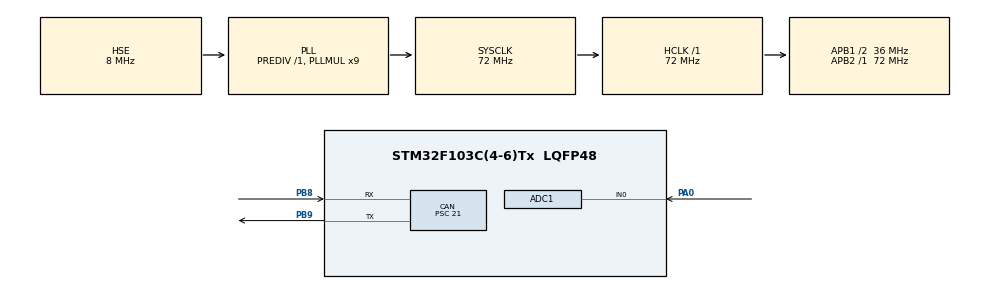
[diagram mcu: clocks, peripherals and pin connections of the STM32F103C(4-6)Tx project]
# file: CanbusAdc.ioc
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ADC1.Channel-0\#ChannelRegularConversion=ADC_CHANNEL_0
ADC1.ContinuousConvMode=ENABLE
ADC1.NbrOfConversion=1
ADC1.NbrOfConversionFlag=1
ADC1.Rank-0\#ChannelRegularConversion=1
ADC1.SamplingTime-0\#ChannelRegularConversion=ADC_SAMPLETIME_55CYCLES_5
ADC1.master=1
CAN.BS1=CAN_BS1_12TQ
CAN.BS2=CAN_BS2_4TQ
CAN.CalculateBaudRate=100840
CAN.CalculateTimeBit=9916
CAN.CalculateTimeQuantum=583.3333333333334
CAN.Prescaler=21
Mcu.Family=STM32F1
Mcu.Name=STM32F103C(4-6)Tx
Mcu.Package=LQFP48
NVIC.PriorityGroup=NVIC_PRIORITYGROUP_4
NVIC.USB_LP_CAN1_RX0_IRQn=true\:0\:0\:false\:false\:true\:true\:true\:true
PA0-WKUP.Signal=ADCx_IN0
PA13.Mode=Serial_Wire
PA13.Signal=SYS_JTMS-SWDIO
PA14.Mode=Serial_Wire
PA14.Signal=SYS_JTCK-SWCLK
PB8.Mode=CAN_Activate
PB8.Signal=CAN_RX
PB9.Mode=CAN_Activate
PB9.Signal=CAN_TX
PD0-OSC_IN.Mode=HSE-External-Oscillator
PD0-OSC_IN.Signal=RCC_OSC_IN
PD1-OSC_OUT.Mode=HSE-External-Oscillator
PD1-OSC_OUT.Signal=RCC_OSC_OUT
ProjectManager.HeapSize=0x200
ProjectManager.StackSize=0x400
ProjectManager.TargetToolchain=STM32CubeIDE
RCC.ADCPresc=RCC_ADCPCLK2_DIV6
RCC.AHBFreq_Value=72000000
RCC.APB1CLKDivider=RCC_HCLK_DIV2
RCC.APB1Freq_Value=36000000
RCC.APB1TimFreq_Value=72000000
RCC.APB2Freq_Value=72000000
RCC.APB2TimFreq_Value=72000000
RCC.HCLKFreq_Value=72000000
RCC.PLLMUL=RCC_PLL_MUL9
RCC.PLLSourceVirtual=RCC_PLLSOURCE_HSE
RCC.SYSCLKFreq_VALUE=72000000
RCC.SYSCLKSource=RCC_SYSCLKSOURCE_PLLCLK
RCC.USBFreq_Value=72000000
SH.ADCx_IN0.0=ADC1_IN0,IN0
board=custom

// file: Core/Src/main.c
/* USER CODE BEGIN Header */
/**
  ******************************************************************************
  * @file           : main.c
  * @brief          : Main program body
  ******************************************************************************
  * @attention
  *
  * Copyright (c) 2024 STMicroelectronics.
  * All rights reserved.
  *
  * This software is licensed under terms that can be found in the LICENSE file
  * in the root directory of this software component.
  * If no LICENSE file comes with this software, it is provided AS-IS.
  *
  ******************************************************************************
  */
/* USER CODE END Header */
#include "main.h"

ADC_HandleTypeDef hadc1;

CAN_HandleTypeDef hcan;

/* USER CODE BEGIN PV */

uint8_t adcData;
uint32_t pTxMailbox;

CAN_TxHeaderTypeDef pHeader;
CAN_FilterTypeDef sFilterConfig;

/* USER CODE END PV */

void SystemClock_Config(void);
static void MX_GPIO_Init(void);
static void MX_CAN_Init(void);
static void MX_ADC1_Init(void);

int main(void)
{

  /* MCU Configuration--------------------------------------------------------*/

  /* Reset of all peripherals, Initializes the Flash interface and the Systick. */
  HAL_Init();

  /* Configure the system clock */
  SystemClock_Config();

  /* Initialize all configured peripherals */
  MX_GPIO_Init();
  MX_CAN_Init();
  MX_ADC1_Init();
  /* USER CODE BEGIN 2 */
  	  //Set transmit parameters
  	  	  pHeader.DLC = 1; // length of message (1 == 8bit message)
  	  	  pHeader.IDE = CAN_ID_STD; // Standard or extended
  	  	  pHeader.RTR = CAN_RTR_DATA; // if you write data it means the card send data
  	  	  pHeader.StdId = 0x0112;

  	  // Set filter parameter
  	  	  sFilterConfig.FilterActivation = ENABLE;
  	  	  sFilterConfig.FilterBank = 0;
  	  	  sFilterConfig.FilterFIFOAssignment = CAN_FILTER_FIFO0;
  	  	  sFilterConfig.FilterIdHigh = 0x0000;
  	  	  sFilterConfig.FilterIdLow = 0x0000;
  	  	  sFilterConfig.FilterMaskIdHigh = 0x0000;
  	  	  sFilterConfig.FilterMaskIdLow = 0x0000;
  	  	  sFilterConfig.FilterMode = CAN_FILTERMODE_IDMASK; // if you want to communicate with actual id number you can choose list
  	  	  sFilterConfig.FilterScale = CAN_FILTERSCALE_16BIT; // 16 bit because i use std id

  	  	  HAL_CAN_ConfigFilter(&hcan, &sFilterConfig);
  	  //Start Can communication
  	  	  HAL_CAN_Start(&hcan);
  	  //Start Adc with DMA
  	  	  HAL_ADC_Start_DMA(&hadc1, &adcData, 1);

  /* USER CODE END 2 */

  /* Infinite loop */
  while (1)
  {

    /* USER CODE BEGIN 3 */
	  HAL_CAN_AddTxMessage(&hcan, &pHeader, &adcData, &pTxMailbox);
  }
  /* USER CODE END 3 */
}

void SystemClock_Config(void)
{
  RCC_OscInitTypeDef RCC_OscInitStruct = {0};
  RCC_ClkInitTypeDef RCC_ClkInitStruct = {0};
  RCC_PeriphCLKInitTypeDef PeriphClkInit = {0};

  /** Initializes the RCC Oscillators according to the specified parameters
  * in the RCC_OscInitTypeDef structure.
  */
  RCC_OscInitStruct.OscillatorType = RCC_OSCILLATORTYPE_HSE;
  RCC_OscInitStruct.HSEState = RCC_HSE_ON;
  RCC_OscInitStruct.HSEPredivValue = RCC_HSE_PREDIV_DIV1;
  RCC_OscInitStruct.HSIState = RCC_HSI_ON;
  RCC_OscInitStruct.PLL.PLLState = RCC_PLL_ON;
  RCC_OscInitStruct.PLL.PLLSource = RCC_PLLSOURCE_HSE;
  RCC_OscInitStruct.PLL.PLLMUL = RCC_PLL_MUL9;
  if (HAL_RCC_OscConfig(&RCC_OscInitStruct) != HAL_OK)
  {
    Error_Handler();
  }

  /** Initializes the CPU, AHB and APB buses clocks
  */
  RCC_ClkInitStruct.ClockType = RCC_CLOCKTYPE_HCLK|RCC_CLOCKTYPE_SYSCLK
                              |RCC_CLOCKTYPE_PCLK1|RCC_CLOCKTYPE_PCLK2;
  RCC_ClkInitStruct.SYSCLKSource = RCC_SYSCLKSOURCE_PLLCLK;
  RCC_ClkInitStruct.AHBCLKDivider = RCC_SYSCLK_DIV1;
  RCC_ClkInitStruct.APB1CLKDivider = RCC_HCLK_DIV2;
  RCC_ClkInitStruct.APB2CLKDivider = RCC_HCLK_DIV1;

  if (HAL_RCC_ClockConfig(&RCC_ClkInitStruct, FLASH_LATENCY_2) != HAL_OK)
  {
    Error_Handler();
  }
  PeriphClkInit.PeriphClockSelection = RCC_PERIPHCLK_ADC;
  PeriphClkInit.AdcClockSelection = RCC_ADCPCLK2_DIV6;
  if (HAL_RCCEx_PeriphCLKConfig(&PeriphClkInit) != HAL_OK)
  {
    Error_Handler();
  }
}

static void MX_ADC1_Init(void)
{

  ADC_ChannelConfTypeDef sConfig = {0};

  /** Common config
  */
  hadc1.Instance = ADC1;
  hadc1.Init.ScanConvMode = ADC_SCAN_DISABLE;
  hadc1.Init.ContinuousConvMode = ENABLE;
  hadc1.Init.DiscontinuousConvMode = DISABLE;
  hadc1.Init.ExternalTrigConv = ADC_SOFTWARE_START;
  hadc1.Init.DataAlign = ADC_DATAALIGN_RIGHT;
  hadc1.Init.NbrOfConversion = 1;
  if (HAL_ADC_Init(&hadc1) != HAL_OK)
  {
    Error_Handler();
  }

  /** Configure Regular Channel
  */
  sConfig.Channel = ADC_CHANNEL_0;
  sConfig.Rank = ADC_REGULAR_RANK_1;
  sConfig.SamplingTime = ADC_SAMPLETIME_55CYCLES_5;
  if (HAL_ADC_ConfigChannel(&hadc1, &sConfig) != HAL_OK)
  {
    Error_Handler();
  }

}

static void MX_CAN_Init(void)
{

  hcan.Instance = CAN1;
  hcan.Init.Prescaler = 21;
  hcan.Init.Mode = CAN_MODE_NORMAL;
  hcan.Init.SyncJumpWidth = CAN_SJW_1TQ;
  hcan.Init.TimeSeg1 = CAN_BS1_12TQ;
  hcan.Init.TimeSeg2 = CAN_BS2_4TQ;
  hcan.Init.TimeTriggeredMode = DISABLE;
  hcan.Init.AutoBusOff = DISABLE;
  hcan.Init.AutoWakeUp = DISABLE;
  hcan.Init.AutoRetransmission = DISABLE;
  hcan.Init.ReceiveFifoLocked = DISABLE;
  hcan.Init.TransmitFifoPriority = DISABLE;
  if (HAL_CAN_Init(&hcan) != HAL_OK)
  {
    Error_Handler();
  }

}

static void MX_GPIO_Init(void)
{

  /* GPIO Ports Clock Enable */
  __HAL_RCC_GPIOD_CLK_ENABLE();
  __HAL_RCC_GPIOA_CLK_ENABLE();
  __HAL_RCC_GPIOB_CLK_ENABLE();

}

void Error_Handler(void)
{
  __disable_irq();
  while (1)
  {
  }
}
